# DSS_HW_ACC_PARAM register map
Vendor: Texas Instruments
Peripheral module from a debugger description file (folder radar).
Registers are 32-bit, read-write, no defined reset value unless marked. A register's access mark holds for its fields unless they carry their own. Offsets are as the file gives them; lines under a group give offsets from that group; [hi:lo] are bit positions; {n}, {i} and the like mark numbered series; 'fields as' and 'values as' point back to an identical list; <NAME> marks a mode.

## DSS_HW_ACC_PARAM
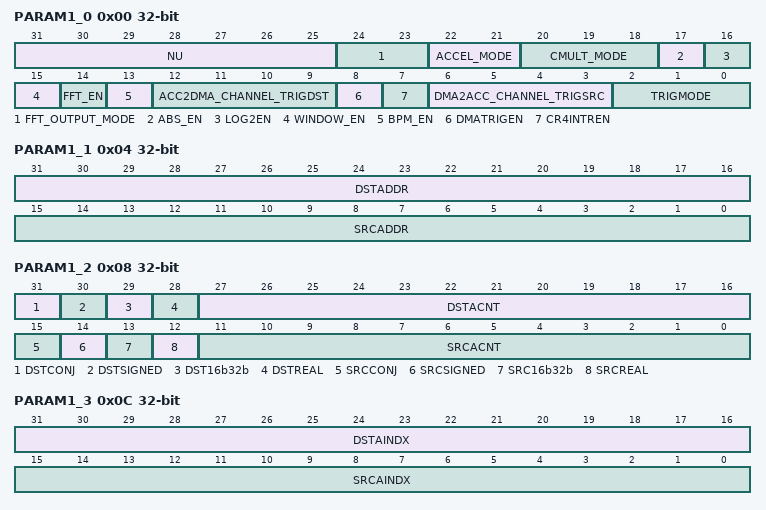
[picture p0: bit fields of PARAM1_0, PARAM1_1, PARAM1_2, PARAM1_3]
0x00 PARAM1_0 — Parameter-set 0 (1st parameter-set out of 16), Register 0
  [31:25] NU — Reserved for future use
  [24:23] FFT_OUTPUT_MODE — Configures the output mode of the FFT Engine path. Refer REG_FFTOUT_MODE in the system spec document. 0xb - Default output (i.e., main data path output is sent out - eg. FFT or Log-Mag output) 10b - Statistics output - Max statistics is sent out (Max valiue on the I arm, Max index on the Q arm) 11b - Statistics output - Sum statistics is sent out
  [22:21] ACCEL_MODE — Configures the mode of operation of the accelerator for the current parameter-set. Refer REG_ACCEL_MODE in the system spec document. 00b - FFT Engine path 01b - CFAR Engine path 10b - Reserved for future use 11b - NULL mode
  [20:18] CMULT_MODE — Configuration for the Complex Multiplier block. Refer REG_CMULT_MODE in the system spec document. 000b - Disabled 001b to 111b - Enabled in one of 7 different modes (as explained in the system spec document)
  [17] ABS_EN — Enable/Disable for Magnitude computation. Refer REG_ABS_EN in the system spec document. When enabled, the magnitude of the input samples coming in to the Log-Magnitude block is calculated and sent out on the I-arm of the output. The Q-arm is made zeros.
  [16] LOG2EN — Enable/Disable for Log2 computation. Refer REG_LOG2_EN in the system spec document. When enabled, the Log2 of the magnitude of the input samples coming in to the Log-Magnitude block is calculated and sent out on the I-arm of the output. The Q-arm is made zeros.
  [15] WINDOW_EN — Enable/Disable for Windowing operation. Refer REG_WINDOW_EN in the system spec document.
  [14] FFT_EN — Enable/Disable for FFT computation. Refer REG_FFT_EN in the system spec document.
  [13] BPM_EN — Enable/Disable for BPM removal operation. Refer REG_BPM_EN in the system spec document. If set (i.e., enabled), then BPM removal is performed prior to feeding samples to the core computational unit.
  [12:9] ACC2DMA_CHANNEL_TRIGDST — Selects which of the 16 DMA channels (allocated to the Radar Accelerator) should be triggered upon completion of the accelerator operation for the current parameter-set. Refer REG_ACC2DMA_TRIGDST in the system spec document.
  [8] DMATRIGEN — Enable/disable trigger to DMA upon completion of the computational operations for the current parameter-set. Refer REG_DMATRIGEN in the system spec document. If enabled, the accelerator will trigger a specified DMA channel, so that the output samples can be shipped to R4F memory or Shared memory. There is a separate 4-bit register (see below), which is used to select which of the 16 DMA channels should be triggered upon completion of the accelerator operation for the current parameter-set.
  [7] CR4INTREN — Enable/disable interrupt to the R4F upon completion of the computational operations for the current parameter-set. Refer REG_INTREN in the system spec document. If enabled, the R4F will receive an interrupt from the Accelerator at the completion of the current parameter-set.
  [6:3] DMA2ACC_CHANNEL_TRIGSRC — This register is only relevant when TRIGMODE = 011b (DMA based trigger). This register selects the bit number in REG_DMA2ACCTRIG for the state machine to monitor in order to trigger the operation for the current parameter-set.
  [2:0] TRIGMODE — Configures the trigger mode to start the computational operations for this parameter-set. Refer REG_TRIGMODE in the system spec document. 000b - Immediate trigger 001b - R4F based software trigger (In this mode, R4F writes a single register bit REG_CR42ACCTRIG to trigger the operation for the current parameter-set. The triggering is based on the state machine monitoring this register bit to be set) 010b - Ping-pong switch based trigger (Whenever the DFE switches from ping-to-pong buffer, or pong-to-ping buffer) 011b - DMA based trigger (In this mode, DMA writes a specific one-hot signature in the 16-bit register REG_DMA2ACCTRIG to trigger the operation for the current parameter-set. The triggering is based on the state machine monitoring bit number DMA2ACC_CHANNEL_TRIGSRC to be set)
0x04 PARAM1_1 — Parameter-set 0 (1st parameter-set out of 16), Register 1
  [31:16] DSTADDR — Destination memory start address from which output samples should be written to. Refer REG_DSTADDR in the system spec document.
  [15:0] SRCADDR — Source memory start address from which to pick input samples from. Refer REG_SRCADDR in the system spec document.
0x08 PARAM1_2 — Parameter-set 0 (1st parameter-set out of 16), Register 2
  [31] DSTCONJ — Enable/Disable Conjugation of the output samples. Refer REG_DSTCONJ in the system spec document. 0 = No conjugation, 1 = Enable conjugation This register only makes sense for complex output case (i.e., Log-Mag is not enabled). It is useful in conjunction with SRCCONJ to derive an IFFT mode (by conjugating at both input and output)
  [30] DSTSIGNED — Signed or Unsigned data in the destination memory. Refer REG_DSTSIGNED in the system spec document. This register enables the output formatter to perform the correct sign-extension and/or saturation operation when writing the 24-bit output as 16-bit aligned or 32-bit aligned data in the destination memory.
  [29] DST16b32b — 16-bit or 32-bit alignment of data in destination memory. Refer REG_DST16b32b in the system spec document. 0 = 16-bit aligned, 1 = 32-bit aligned
  [28] DSTREAL — Real or Complex data in the destination memory. Refer REG_DSTREAL in the system spec document. 0 = Complex output, 1 = Real output Real output is generally useful when Magnitude or Log-Magnitude computation is enabled.
  [27:16] DSTACNT — Destination sample count. Refer REG_DSTACNT in the system spec document. Zero-based count of number of samples till which to write to the destination memory for each iteration. Note that this must be equal to or less than REG_SRCANT+any zero pads (applicable in case of FFT). Note that the actual number of samples written to destination memory would be REG_DSTACNT+1-REG_DST_SKIP_INIT.
  [15] SRCCONJ — Enable/Disable Conjugation of the input samples. Refer REG_SRCCONJ in the system spec document. 0 = No conjugation, 1 = Enable conjugation This register only makes sense for complex input case. It is useful in conjunction with DSTCONJ to derive an IFFT mode (by conjugating at both input and output)
  [14] SRCSIGNED — Signed or Unsigned data in the source memory. Refer REG_SRCSIGNED in the system spec document. This register is only relevant for 16-bit aligned data in source memory, because that is when sign-extension may be required to convert to internal 24-bit width. 0 = Unsigned, 1 = Signed.
  [13] SRC16b32b — 16-bit or 32-bit alignment of data in source memory. Refer REG_SRC16b32b in the system spec document. 0 = 16-bit aligned, 1 = 32-bit aligned
  [12] SRCREAL — Real or Complex data in the source memory. Refer REG_SRCREAL in the system spec document. 0 = Complex input, 1 = Real input
  [11:0] SRCACNT — Source sample count. Refer REG_SRCACNT in the system spec document. Zero-based count of number of samples to read from the source memory for each iteration.
0x0C PARAM1_3 — Parameter-set 0 (1st parameter-set out of 16), Register 3
  [31:16] DSTAINDX — Destination sample index increment. Refer REG_DSTAINDX in the system spec document. Specifies the number of bytes separating adjacent samples in the destination memory.
  [15:0] SRCAINDX — Source sample index increment. Refer REG_SRCAINDX in the system spec document. Specifies the number of bytes separating adjacent samples in the source memory.
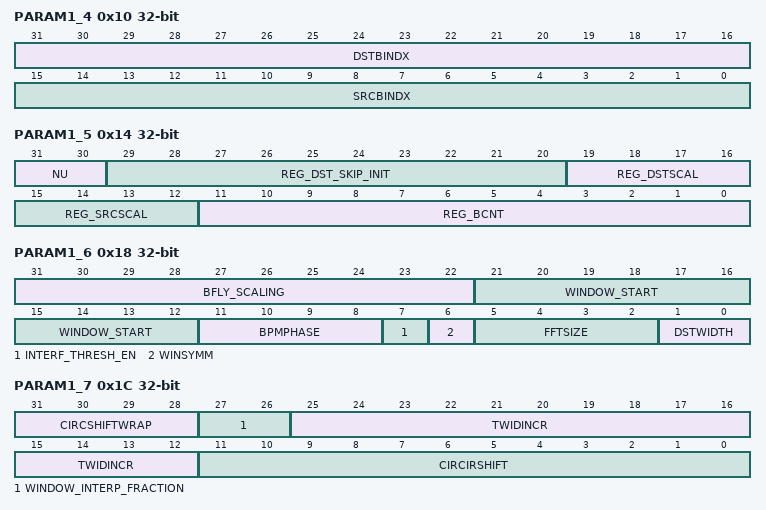
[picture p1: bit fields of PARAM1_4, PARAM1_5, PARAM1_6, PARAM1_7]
0x10 PARAM1_4 — Parameter-set 0 (1st parameter-set out of 16), Register 4
  [31:16] DSTBINDX — Destination Offset across successive iterations. Refer REG_DSTBINDX in the system spec document. Specifies the number of bytes separating the start address of samples for successive iterations in the destination memory.
  [15:0] SRCBINDX — Source Offset across successive iterations. Refer REG_SRCBINDX in the system spec document. Specifies the number of bytes separating the start address of samples for successive iterations in the source memory.
0x14 PARAM1_5 — Parameter-set 0 (1st parameter-set out of 16), Register 5
  [31:30] NU — Reserved for future use
  [29:20] REG_DST_SKIP_INIT — Destination skip sample count. Refer REG_DST_SKIP_INIT in the system spec document. Number of samples to skip in the beginning (for each iteration) before writing samples to the destination memory.
  [19:16] REG_DSTSCAL — Output scaling. Refer REG_DSTSCAL in the system spec document. Specifies a programmable scaling, via right bit-shift, from 0 bits to 8 bits, for the output samples.
  [15:12] REG_SRCSCAL — Input scaling. Refer REG_SRCSCAL in the system spec document. Specifies a programmable scaling, via right bit-shift, from 0 bits to 8 bits, for the input samples.
  [11:0] REG_BCNT — Number of iterations. Refer REG_BCNT in the system spec document.
0x18 PARAM1_6 — Parameter-set 0 (1st parameter-set out of 16), Register 6
  [31:22] BFLY_SCALING — Specifies the butterfly scaling for each of the 10 butterfly stages. Refer REG_BFLY_SCALING in the system spec document.
  [21:12] WINDOW_START — Specifies the starting address of the window function in the Window RAM. Refer REG_WINDOW_START in the system spec document.
  [11:8] BPMPHASE — Specifies the starting phase of the BPM pattern to be applied. Refer REG_BPMPHASE in the system spec document.
  [7] INTERF_THRESH_EN — Enable/Disable for interference zeroing out. Refer REG_INTERF_THRESH_EN in the system spec document. If set, then input samples with large magnitude are zeroed out. Also see REG_INTERF_THRESH register which is a common register, not part of the parameter-set.
  [6] WINSYMM — Indicates whether the window function is symmetric or not. Refer REG_WIMSYMM in the system spec document. If this register bit is set, only the first half the window coefficients are expected to be present in the window RAM. The same coefficients are read in reverse direction for the second half.
  [5:2] FFTSIZE — Specifies FFT size. Actual FFT size is equal to 2 raised to the register value. Refer REG_FFTSIZE in the system spec document. For example, FFTSIZE = 0110b corresponds to actual FFT size of 2^6 = 64. Supported values are [1..10], which correspond to FFT sizes [2..1024].
  [1:0] DSTWIDTH — Must be kept as 00b. Reserved for future use. (This was originally meant for bit-packing , such as bitwidths of 18-bits, 21-bits, etc. which is no longer supported).
0x1C PARAM1_7 — Parameter-set 0 (1st parameter-set out of 16), Register 7
  [31:28] CIRCSHIFTWRAP — Indicates at what number (power-of-2) the sample counter value should wraparound, when using circular shift. Refer REG_CIRCSHIFTWRAP in the system spec document.
  [27:26] WINDOW_INTERP_FRACTION — Configures linear interpolation for the window coefficients, which is relevant for large-size FFT computation (i.e., FFT sizes of 2K, 4K) that is obtained via stitching multiple smaller-size FFTs. Refer REG_WINDOW_INTERP_FRACTION in the system spec document.
  [25:12] TWIDINCR — Configures the nature of frequency de-rotation done in the Complex Multiplier block. This meaning of this register depends on the Complex Multipler mode of operation. Refer REG_TWIDINCR in the system spec document.
  [11:0] CIRCIRSHIFT — Specifies the circular shift (offset in samples) that should be applied to the sequence of input samples before feeding them to the core computational unit. Refer REG_SRCSHIFT in the system spec document.
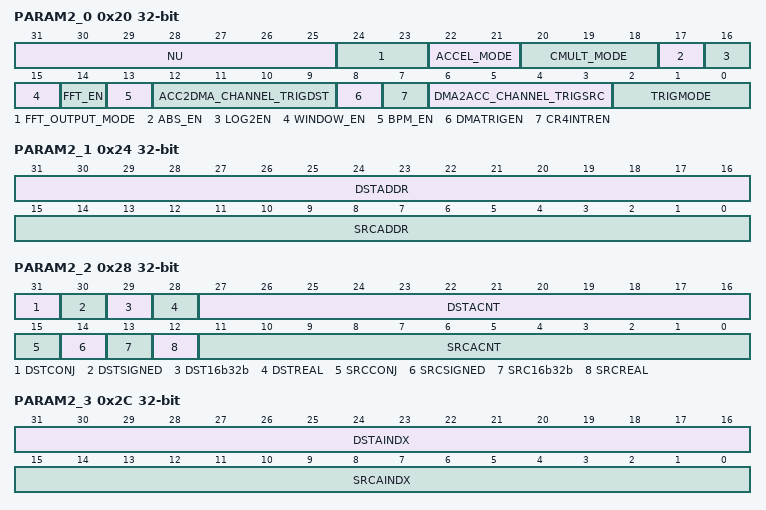
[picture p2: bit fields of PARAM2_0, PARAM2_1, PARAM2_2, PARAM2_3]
0x20 PARAM2_0 — Parameter-set 1 (2nd parameter-set out of 16), Register 0
  [31:25] NU — Refer to PARAM1* Description
  [24:23] FFT_OUTPUT_MODE — Refer to PARAM1* Description
  [22:21] ACCEL_MODE — Refer to PARAM1* Description
  [20:18] CMULT_MODE — Refer to PARAM1* Description
  [17] ABS_EN — Refer to PARAM1* Description
  [16] LOG2EN — Refer to PARAM1* Description
  [15] WINDOW_EN — Refer to PARAM1* Description
  [14] FFT_EN — Refer to PARAM1* Description
  [13] BPM_EN — Refer to PARAM1* Description
  [12:9] ACC2DMA_CHANNEL_TRIGDST — Refer to PARAM1* Description
  [8] DMATRIGEN — Refer to PARAM1* Description
  [7] CR4INTREN — Refer to PARAM1* Description
  [6:3] DMA2ACC_CHANNEL_TRIGSRC — Refer to PARAM1* Description
  [2:0] TRIGMODE — Refer to PARAM1* Description
0x24 PARAM2_1 — Parameter-set 1 (2nd parameter-set out of 16), Register 1
  [31:16] DSTADDR — Refer to PARAM1* Description
  [15:0] SRCADDR — Refer to PARAM1* Description
0x28 PARAM2_2 — Parameter-set 1 (2nd parameter-set out of 16), Register 2
  [31] DSTCONJ — Refer to PARAM1* Description
  [30] DSTSIGNED — Refer to PARAM1* Description
  [29] DST16b32b — Refer to PARAM1* Description
  [28] DSTREAL — Refer to PARAM1* Description
  [27:16] DSTACNT — Refer to PARAM1* Description
  [15] SRCCONJ — Refer to PARAM1* Description
  [14] SRCSIGNED — Refer to PARAM1* Description
  [13] SRC16b32b — Refer to PARAM1* Description
  [12] SRCREAL — Refer to PARAM1* Description
  [11:0] SRCACNT — Refer to PARAM1* Description
0x2C PARAM2_3 — Parameter-set 1 (2nd parameter-set out of 16), Register 3
  [31:16] DSTAINDX — Refer to PARAM1* Description
  [15:0] SRCAINDX — Refer to PARAM1* Description
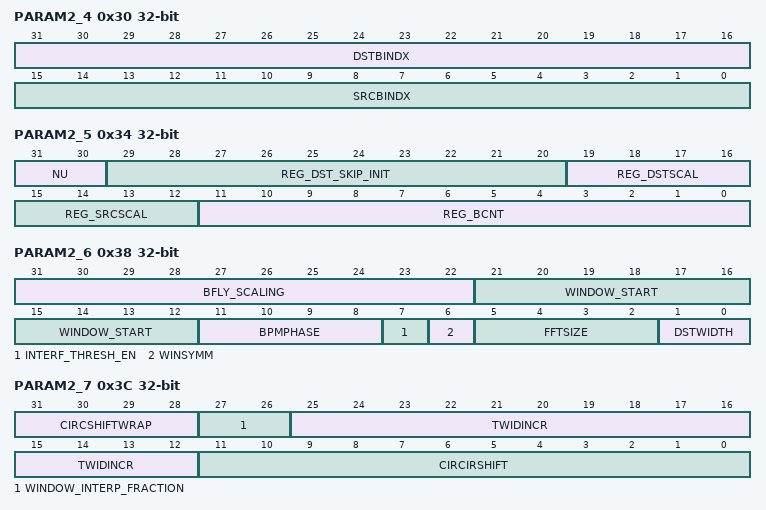
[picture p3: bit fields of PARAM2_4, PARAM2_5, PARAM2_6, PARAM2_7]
0x30 PARAM2_4 — Parameter-set 1 (2nd parameter-set out of 16), Register 4
  [31:16] DSTBINDX — Refer to PARAM1* Description
  [15:0] SRCBINDX — Refer to PARAM1* Description
0x34 PARAM2_5 — Parameter-set 1 (2nd parameter-set out of 16), Register 5
  [31:30] NU — Refer to PARAM1* Description
  [29:20] REG_DST_SKIP_INIT — Refer to PARAM1* Description
  [19:16] REG_DSTSCAL — Refer to PARAM1* Description
  [15:12] REG_SRCSCAL — Refer to PARAM1* Description
  [11:0] REG_BCNT — Refer to PARAM1* Description
0x38 PARAM2_6 — Parameter-set 1 (2nd parameter-set out of 16), Register 6
  [31:22] BFLY_SCALING — Refer to PARAM1* Description
  [21:12] WINDOW_START — Refer to PARAM1* Description
  [11:8] BPMPHASE — Refer to PARAM1* Description
  [7] INTERF_THRESH_EN — Refer to PARAM1* Description
  [6] WINSYMM — Refer to PARAM1* Description
  [5:2] FFTSIZE — Refer to PARAM1* Description
  [1:0] DSTWIDTH — Refer to PARAM1* Description
0x3C PARAM2_7 — Parameter-set 1 (2nd parameter-set out of 16), Register 7
  [31:28] CIRCSHIFTWRAP — Refer to PARAM1* Description
  [27:26] WINDOW_INTERP_FRACTION — Refer to PARAM1* Description
  [25:12] TWIDINCR — Refer to PARAM1* Description
  [11:0] CIRCIRSHIFT — Refer to PARAM1* Description
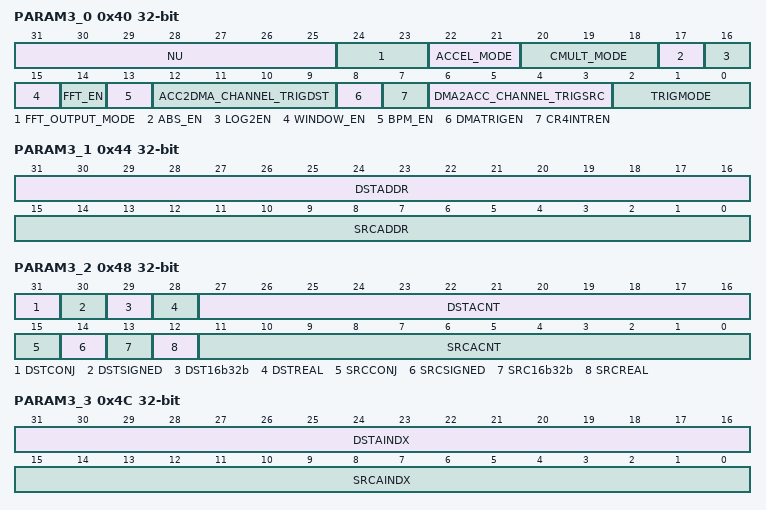
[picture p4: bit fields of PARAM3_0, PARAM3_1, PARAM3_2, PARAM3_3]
0x40 PARAM3_0 — Parameter-set 2 (3rd parameter-set out of 16), Register 0
  fields as PARAM2_0
0x44 PARAM3_1 — Parameter-set 2 (3rd parameter-set out of 16), Register 1
  fields as PARAM2_1
0x48 PARAM3_2 — Parameter-set 2 (3rd parameter-set out of 16), Register 2
  fields as PARAM2_2
0x4C PARAM3_3 — Parameter-set 2 (3rd parameter-set out of 16), Register 3
  fields as PARAM2_3
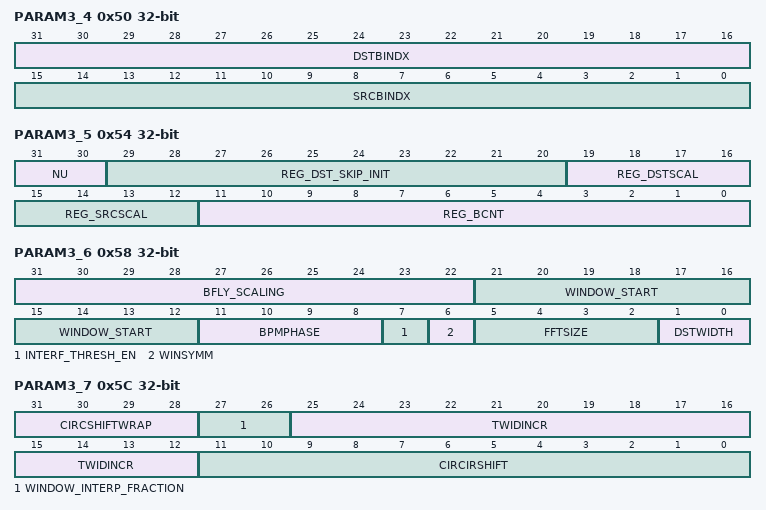
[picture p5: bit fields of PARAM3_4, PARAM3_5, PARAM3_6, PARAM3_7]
0x50 PARAM3_4 — Parameter-set 2 (3rd parameter-set out of 16), Register 4
  fields as PARAM2_4
0x54 PARAM3_5 — Parameter-set 2 (3rd parameter-set out of 16), Register 5
  fields as PARAM2_5
0x58 PARAM3_6 — Parameter-set 2 (3rd parameter-set out of 16), Register 6
  fields as PARAM2_6
0x5C PARAM3_7 — Parameter-set 2 (3rd parameter-set out of 16), Register 7
  fields as PARAM2_7
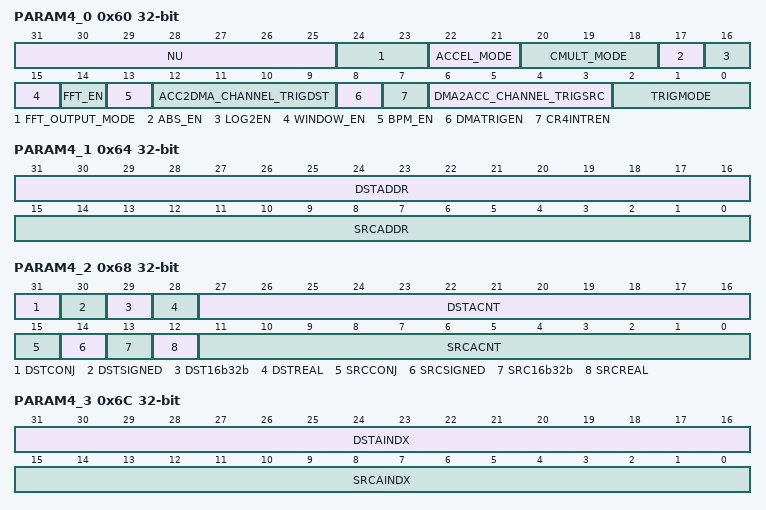
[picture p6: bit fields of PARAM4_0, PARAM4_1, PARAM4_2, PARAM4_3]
0x60 PARAM4_0 — Parameter-set 3 (4th parameter-set out of 16), Register 0
  fields as PARAM2_0
0x64 PARAM4_1 — Parameter-set 3 (4th parameter-set out of 16), Register 1
  fields as PARAM2_1
0x68 PARAM4_2 — Parameter-set 3 (4th parameter-set out of 16), Register 2
  fields as PARAM2_2
0x6C PARAM4_3 — Parameter-set 3 (4th parameter-set out of 16), Register 3
  fields as PARAM2_3
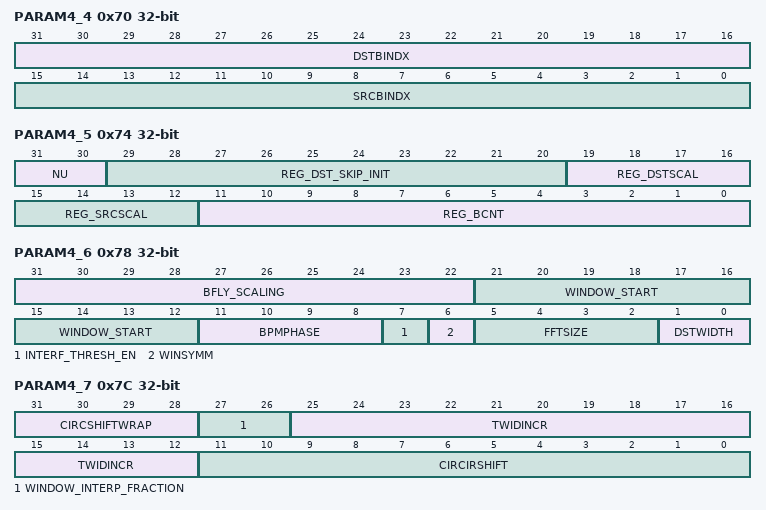
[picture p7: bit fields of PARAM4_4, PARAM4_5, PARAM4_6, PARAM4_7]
0x70 PARAM4_4 — Parameter-set 3 (4th parameter-set out of 16), Register 4
  fields as PARAM2_4
0x74 PARAM4_5 — Parameter-set 3 (4th parameter-set out of 16), Register 5
  fields as PARAM2_5
0x78 PARAM4_6 — Parameter-set 3 (4th parameter-set out of 16), Register 6
  fields as PARAM2_6
0x7C PARAM4_7 — Parameter-set 3 (4th parameter-set out of 16), Register 7
  fields as PARAM2_7
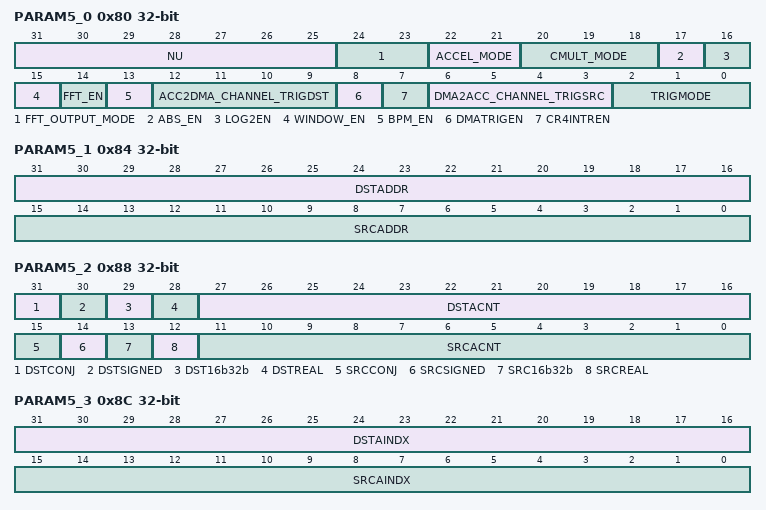
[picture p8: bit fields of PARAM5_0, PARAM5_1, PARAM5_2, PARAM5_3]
0x80 PARAM5_0 — Parameter-set 4 (5th parameter-set out of 16), Register 0
  fields as PARAM2_0
0x84 PARAM5_1 — Parameter-set 4 (5th parameter-set out of 16), Register 1
  fields as PARAM2_1
0x88 PARAM5_2 — Parameter-set 4 (5th parameter-set out of 16), Register 2
  fields as PARAM2_2
0x8C PARAM5_3 — Parameter-set 4 (5th parameter-set out of 16), Register 3
  fields as PARAM2_3
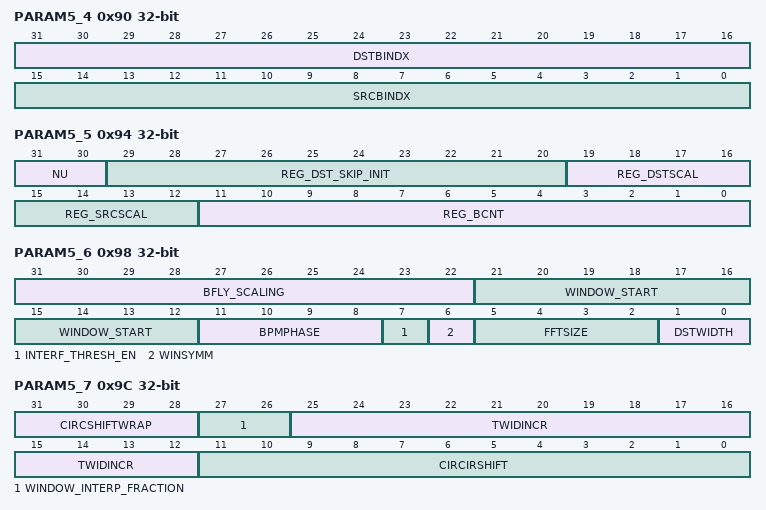
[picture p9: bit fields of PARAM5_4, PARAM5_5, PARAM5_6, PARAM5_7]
0x90 PARAM5_4 — Parameter-set 4 (5th parameter-set out of 16), Register 4
  fields as PARAM2_4
0x94 PARAM5_5 — Parameter-set 4 (5th parameter-set out of 16), Register 5
  fields as PARAM2_5
0x98 PARAM5_6 — Parameter-set 4 (5th parameter-set out of 16), Register 6
  fields as PARAM2_6
0x9C PARAM5_7 — Parameter-set 4 (5th parameter-set out of 16), Register 7
  fields as PARAM2_7
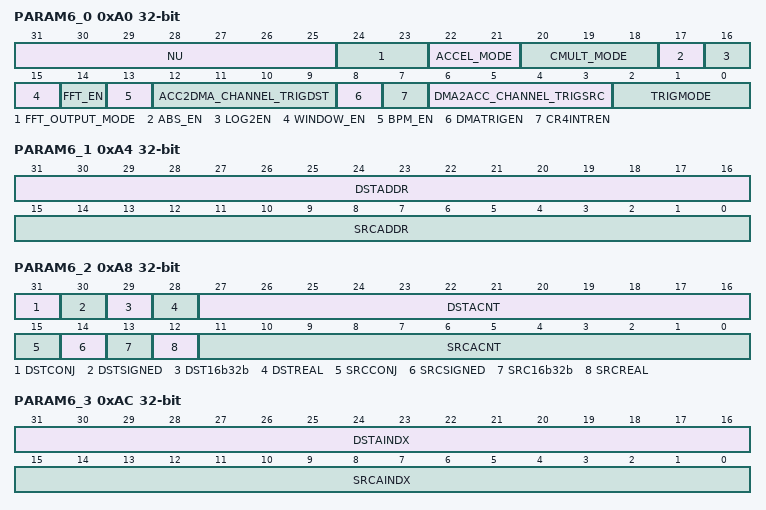
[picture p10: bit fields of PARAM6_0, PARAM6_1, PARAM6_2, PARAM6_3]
0xA0 PARAM6_0 — Parameter-set 5 (6th parameter-set out of 16), Register 0
  fields as PARAM2_0
0xA4 PARAM6_1 — Parameter-set 5 (6th parameter-set out of 16), Register 1
  fields as PARAM2_1
0xA8 PARAM6_2 — Parameter-set 5 (6th parameter-set out of 16), Register 2
  fields as PARAM2_2
0xAC PARAM6_3 — Parameter-set 5 (6th parameter-set out of 16), Register 3
  fields as PARAM2_3
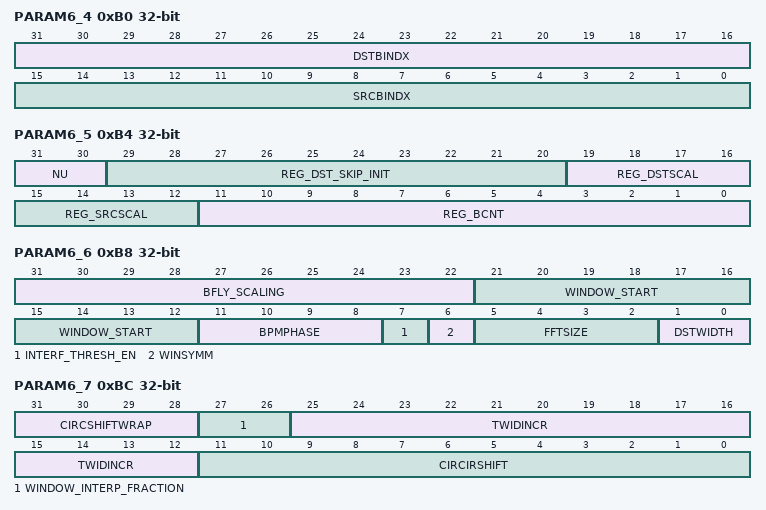
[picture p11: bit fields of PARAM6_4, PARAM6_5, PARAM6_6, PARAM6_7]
0xB0 PARAM6_4 — Parameter-set 5 (6th parameter-set out of 16), Register 4
  fields as PARAM2_4
0xB4 PARAM6_5 — Parameter-set 5 (6th parameter-set out of 16), Register 5
  fields as PARAM2_5
0xB8 PARAM6_6 — Parameter-set 5 (6th parameter-set out of 16), Register 6
  fields as PARAM2_6
0xBC PARAM6_7 — Parameter-set 5 (6th parameter-set out of 16), Register 7
  fields as PARAM2_7
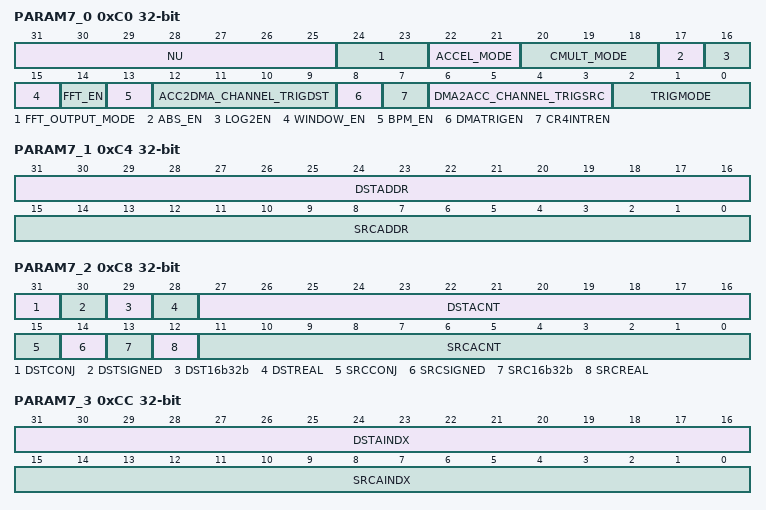
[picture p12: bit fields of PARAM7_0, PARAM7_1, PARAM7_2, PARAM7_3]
0xC0 PARAM7_0 — Parameter-set 6 (7th parameter-set out of 16), Register 0
  fields as PARAM2_0
0xC4 PARAM7_1 — Parameter-set 6 (7th parameter-set out of 16), Register 1
  fields as PARAM2_1
0xC8 PARAM7_2 — Parameter-set 6 (7th parameter-set out of 16), Register 2
  fields as PARAM2_2
0xCC PARAM7_3 — Parameter-set 6 (7th parameter-set out of 16), Register 3
  fields as PARAM2_3
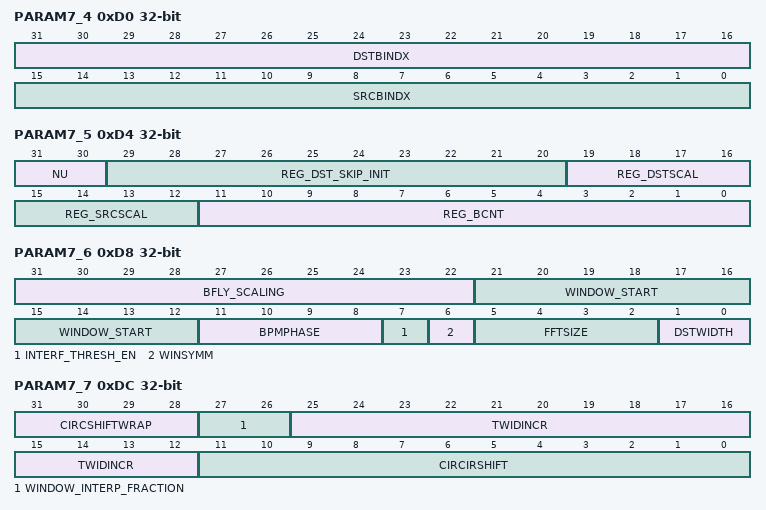
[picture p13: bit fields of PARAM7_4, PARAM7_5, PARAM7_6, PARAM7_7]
0xD0 PARAM7_4 — Parameter-set 6 (7th parameter-set out of 16), Register 4
  fields as PARAM2_4
0xD4 PARAM7_5 — Parameter-set 6 (7th parameter-set out of 16), Register 5
  fields as PARAM2_5
0xD8 PARAM7_6 — Parameter-set 6 (7th parameter-set out of 16), Register 6
  fields as PARAM2_6
0xDC PARAM7_7 — Parameter-set 6 (7th parameter-set out of 16), Register 7
  fields as PARAM2_7
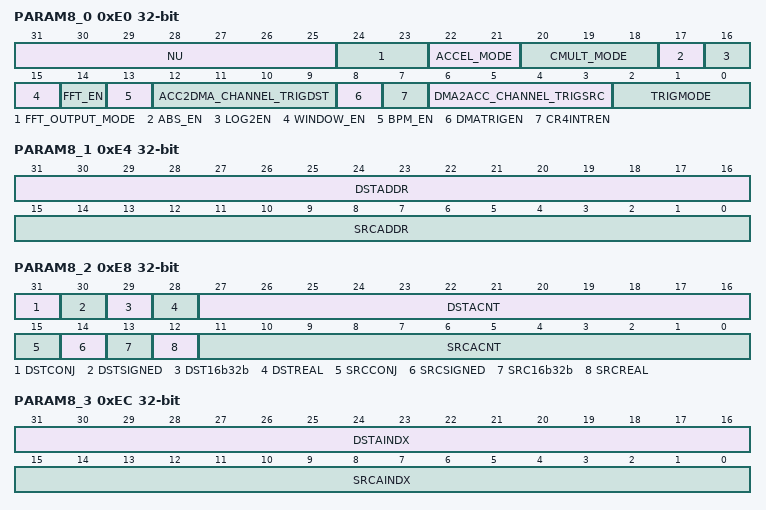
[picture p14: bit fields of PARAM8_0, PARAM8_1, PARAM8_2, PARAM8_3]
0xE0 PARAM8_0 — Parameter-set 7 (8th parameter-set out of 16), Register 0
  fields as PARAM2_0
0xE4 PARAM8_1 — Parameter-set 7 (8th parameter-set out of 16), Register 1
  fields as PARAM2_1
0xE8 PARAM8_2 — Parameter-set 7 (8th parameter-set out of 16), Register 2
  fields as PARAM2_2
0xEC PARAM8_3 — Parameter-set 7 (8th parameter-set out of 16), Register 3
  fields as PARAM2_3
0xF0 PARAM8_4 — Parameter-set 7 (8th parameter-set out of 16), Register 4
  fields as PARAM2_4
0xF4 PARAM8_5 — Parameter-set 7 (8th parameter-set out of 16), Register 5
  fields as PARAM2_5
0xF8 PARAM8_6 — Parameter-set 7 (8th parameter-set out of 16), Register 6
  fields as PARAM2_6
0xFC PARAM8_7 — Parameter-set 7 (8th parameter-set out of 16), Register 7
  fields as PARAM2_7
0x100 PARAM9_0 — Parameter-set 8 (9th parameter-set out of 16), Register 0
  fields as PARAM2_0
0x104 PARAM9_1 — Parameter-set 8 (9th parameter-set out of 16), Register 1
  fields as PARAM2_1
0x108 PARAM9_2 — Parameter-set 8 (9th parameter-set out of 16), Register 2
  fields as PARAM2_2
0x10C PARAM9_3 — Parameter-set 8 (9th parameter-set out of 16), Register 3
  fields as PARAM2_3
0x110 PARAM9_4 — Parameter-set 8 (9th parameter-set out of 16), Register 4
  fields as PARAM2_4
0x114 PARAM9_5 — Parameter-set 8 (9th parameter-set out of 16), Register 5
  fields as PARAM2_5
0x118 PARAM9_6 — Parameter-set 8 (9th parameter-set out of 16), Register 6
  fields as PARAM2_6
0x11C PARAM9_7 — Parameter-set 8 (9th parameter-set out of 16), Register 7
  fields as PARAM2_7
0x120 PARAM10_0 — Parameter-set 9 (10th parameter-set out of 16), Register 0
  fields as PARAM2_0
0x124 PARAM10_1 — Parameter-set 9 (10th parameter-set out of 16), Register 1
  fields as PARAM2_1
0x128 PARAM10_2 — Parameter-set 9 (10th parameter-set out of 16), Register 2
  fields as PARAM2_2
0x12C PARAM10_3 — Parameter-set 9 (10th parameter-set out of 16), Register 3
  fields as PARAM2_3
0x130 PARAM10_4 — Parameter-set 9 (10th parameter-set out of 16), Register 4
  fields as PARAM2_4
0x134 PARAM10_5 — Parameter-set 9 (10th parameter-set out of 16), Register 5
  fields as PARAM2_5
0x138 PARAM10_6 — Parameter-set 9 (10th parameter-set out of 16), Register 6
  fields as PARAM2_6
0x13C PARAM10_7 — Parameter-set 9 (10th parameter-set out of 16), Register 7
  fields as PARAM2_7
0x140 PARAM11_0 — Parameter-set 10 (11th parameter-set out of 16), Register 0
  fields as PARAM2_0
0x144 PARAM11_1 — Parameter-set 10 (11th parameter-set out of 16), Register 1
  fields as PARAM2_1
0x148 PARAM11_2 — Parameter-set 10 (11th parameter-set out of 16), Register 2
  fields as PARAM2_2
0x14C PARAM11_3 — Parameter-set 10 (11th parameter-set out of 16), Register 3
  fields as PARAM2_3
0x150 PARAM11_4 — Parameter-set 10 (11th parameter-set out of 16), Register 4
  fields as PARAM2_4
0x154 PARAM11_5 — Parameter-set 10 (11th parameter-set out of 16), Register 5
  fields as PARAM2_5
0x158 PARAM11_6 — Parameter-set 10 (11th parameter-set out of 16), Register 6
  fields as PARAM2_6
0x15C PARAM11_7 — Parameter-set 10 (11th parameter-set out of 16), Register 7
  fields as PARAM2_7
0x160 PARAM12_0 — Parameter-set 11 (12th parameter-set out of 16), Register 0
  fields as PARAM2_0
0x164 PARAM12_1 — Parameter-set 11 (12th parameter-set out of 16), Register 1
  fields as PARAM2_1
0x168 PARAM12_2 — Parameter-set 11 (12th parameter-set out of 16), Register 2
  fields as PARAM2_2
0x16C PARAM12_3 — Parameter-set 11 (12th parameter-set out of 16), Register 3
  fields as PARAM2_3
0x170 PARAM12_4 — Parameter-set 11 (12th parameter-set out of 16), Register 4
  fields as PARAM2_4
0x174 PARAM12_5 — Parameter-set 11 (12th parameter-set out of 16), Register 5
  fields as PARAM2_5
0x178 PARAM12_6 — Parameter-set 11 (12th parameter-set out of 16), Register 6
  fields as PARAM2_6
0x17C PARAM12_7 — Parameter-set 11 (12th parameter-set out of 16), Register 7
  fields as PARAM2_7
0x180 PARAM13_0 — Parameter-set 12 (13th parameter-set out of 16), Register 0
  fields as PARAM2_0
0x184 PARAM13_1 — Parameter-set 12 (13th parameter-set out of 16), Register 1
  fields as PARAM2_1
0x188 PARAM13_2 — Parameter-set 12 (13th parameter-set out of 16), Register 2
  fields as PARAM2_2
0x18C PARAM13_3 — Parameter-set 12 (13th parameter-set out of 16), Register 3
  fields as PARAM2_3
0x190 PARAM13_4 — Parameter-set 12 (13th parameter-set out of 16), Register 4
  fields as PARAM2_4
0x194 PARAM13_5 — Parameter-set 12 (13th parameter-set out of 16), Register 5
  fields as PARAM2_5
0x198 PARAM13_6 — Parameter-set 12 (13th parameter-set out of 16), Register 6
  fields as PARAM2_6
0x19C PARAM13_7 — Parameter-set 12 (13th parameter-set out of 16), Register 7
  fields as PARAM2_7
0x1A0 PARAM14_0 — Parameter-set 13 (14th parameter-set out of 16), Register 0
  fields as PARAM2_0
0x1A4 PARAM14_1 — Parameter-set 13 (14th parameter-set out of 16), Register 1
  fields as PARAM2_1
0x1A8 PARAM14_2 — Parameter-set 13 (14th parameter-set out of 16), Register 2
  fields as PARAM2_2
0x1AC PARAM14_3 — Parameter-set 13 (14th parameter-set out of 16), Register 3
  fields as PARAM2_3
0x1B0 PARAM14_4 — Parameter-set 13 (14th parameter-set out of 16), Register 4
  fields as PARAM2_4
0x1B4 PARAM14_5 — Parameter-set 13 (14th parameter-set out of 16), Register 5
  fields as PARAM2_5
0x1B8 PARAM14_6 — Parameter-set 13 (14th parameter-set out of 16), Register 6
  fields as PARAM2_6
0x1BC PARAM14_7 — Parameter-set 13 (14th parameter-set out of 16), Register 7
  fields as PARAM2_7
0x1C0 PARAM15_0 — Parameter-set 14 (15th parameter-set out of 16), Register 0
  fields as PARAM2_0
0x1C4 PARAM15_1 — Parameter-set 14 (15th parameter-set out of 16), Register 1
  fields as PARAM2_1
0x1C8 PARAM15_2 — Parameter-set 14 (15th parameter-set out of 16), Register 2
  fields as PARAM2_2
0x1CC PARAM15_3 — Parameter-set 14 (15th parameter-set out of 16), Register 3
  fields as PARAM2_3
0x1D0 PARAM15_4 — Parameter-set 14 (15th parameter-set out of 16), Register 4
  fields as PARAM2_4
0x1D4 PARAM15_5 — Parameter-set 14 (15th parameter-set out of 16), Register 5
  fields as PARAM2_5
0x1D8 PARAM15_6 — Parameter-set 14 (15th parameter-set out of 16), Register 6
  fields as PARAM2_6
0x1DC PARAM15_7 — Parameter-set 14 (15th parameter-set out of 16), Register 7
  fields as PARAM2_7
0x1E0 PARAM16_0 — Parameter-set 15 (16th parameter-set out of 16), Register 0
  fields as PARAM2_0
0x1E4 PARAM16_1 — Parameter-set 15 (16th parameter-set out of 16), Register 1
  fields as PARAM2_1
0x1E8 PARAM16_2 — Parameter-set 15 (16th parameter-set out of 16), Register 2
  fields as PARAM2_2
0x1EC PARAM16_3 — Parameter-set 15 (16th parameter-set out of 16), Register 3
  fields as PARAM2_3
0x1F0 PARAM16_4 — Parameter-set 15 (16th parameter-set out of 16), Register 4
  fields as PARAM2_4
0x1F4 PARAM16_5 — Parameter-set 15 (16th parameter-set out of 16), Register 5
  fields as PARAM2_5
0x1F8 PARAM16_6 — Parameter-set 15 (16th parameter-set out of 16), Register 6
  fields as PARAM2_6
0x1FC PARAM16_7 — Parameter-set 15 (16th parameter-set out of 16), Register 7
  fields as PARAM2_7
